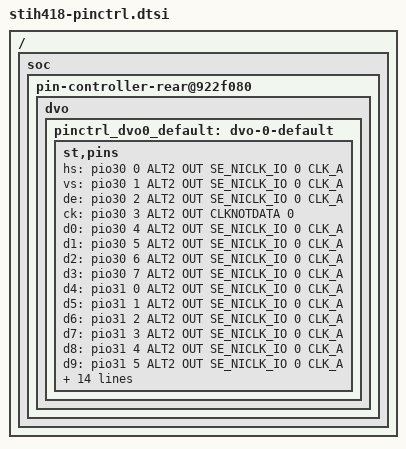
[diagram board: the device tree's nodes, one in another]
// SPDX-License-Identifier: GPL-2.0-only
/*
 * Copyright (C) 2023 Alain Volmat
 * Author: Alain Volmat <avolmat@me.com>
 */
#include "st-pincfg.h"
/ {
	soc {
		pin-controller-rear@922f080 {
			dvo {
  				pinctrl_dvo0_default: dvo-0-default {
					st,pins {
						hs = <&pio30 0 ALT2 OUT SE_NICLK_IO 0 CLK_A>;
						vs = <&pio30 1 ALT2 OUT SE_NICLK_IO 0 CLK_A>;
						de = <&pio30 2 ALT2 OUT SE_NICLK_IO 0 CLK_A>;
						ck = <&pio30 3 ALT2 OUT CLKNOTDATA 0>;
						d0 = <&pio30 4 ALT2 OUT SE_NICLK_IO 0 CLK_A>;
						d1 = <&pio30 5 ALT2 OUT SE_NICLK_IO 0 CLK_A>;
						d2 = <&pio30 6 ALT2 OUT SE_NICLK_IO 0 CLK_A>;
						d3 = <&pio30 7 ALT2 OUT SE_NICLK_IO 0 CLK_A>;
						d4 = <&pio31 0 ALT2 OUT SE_NICLK_IO 0 CLK_A>;
						d5 = <&pio31 1 ALT2 OUT SE_NICLK_IO 0 CLK_A>;
						d6 = <&pio31 2 ALT2 OUT SE_NICLK_IO 0 CLK_A>;
						d7 = <&pio31 3 ALT2 OUT SE_NICLK_IO 0 CLK_A>;
						d8 = <&pio31 4 ALT2 OUT SE_NICLK_IO 0 CLK_A>;
						d9 = <&pio31 5 ALT2 OUT SE_NICLK_IO 0 CLK_A>;
						d10 = <&pio31 6 ALT2 OUT SE_NICLK_IO 0 CLK_A>;
						d11 = <&pio31 7 ALT2 OUT SE_NICLK_IO 0 CLK_A>;
						d12 = <&pio32 0 ALT2 OUT SE_NICLK_IO 0 CLK_A>;
						d13 = <&pio32 1 ALT2 OUT SE_NICLK_IO 0 CLK_A>;
						d14 = <&pio32 2 ALT2 OUT SE_NICLK_IO 0 CLK_A>;
						d15 = <&pio32 3 ALT2 OUT SE_NICLK_IO 0 CLK_A>;
						d16 = <&pio32 4 ALT2 OUT SE_NICLK_IO 0 CLK_A>;
						d17 = <&pio32 5 ALT2 OUT SE_NICLK_IO 0 CLK_A>;
						d18 = <&pio32 6 ALT2 OUT SE_NICLK_IO 0 CLK_A>;
						d19 = <&pio32 7 ALT2 OUT SE_NICLK_IO 0 CLK_A>;
						d20 = <&pio33 0 ALT2 OUT SE_NICLK_IO 0 CLK_A>;
						d21 = <&pio33 1 ALT2 OUT SE_NICLK_IO 0 CLK_A>;
						d22 = <&pio33 2 ALT2 OUT SE_NICLK_IO 0 CLK_A>;
						d23 = <&pio33 3 ALT2 OUT SE_NICLK_IO 0 CLK_A>;
					};
				};
			};
		};
	};
};
